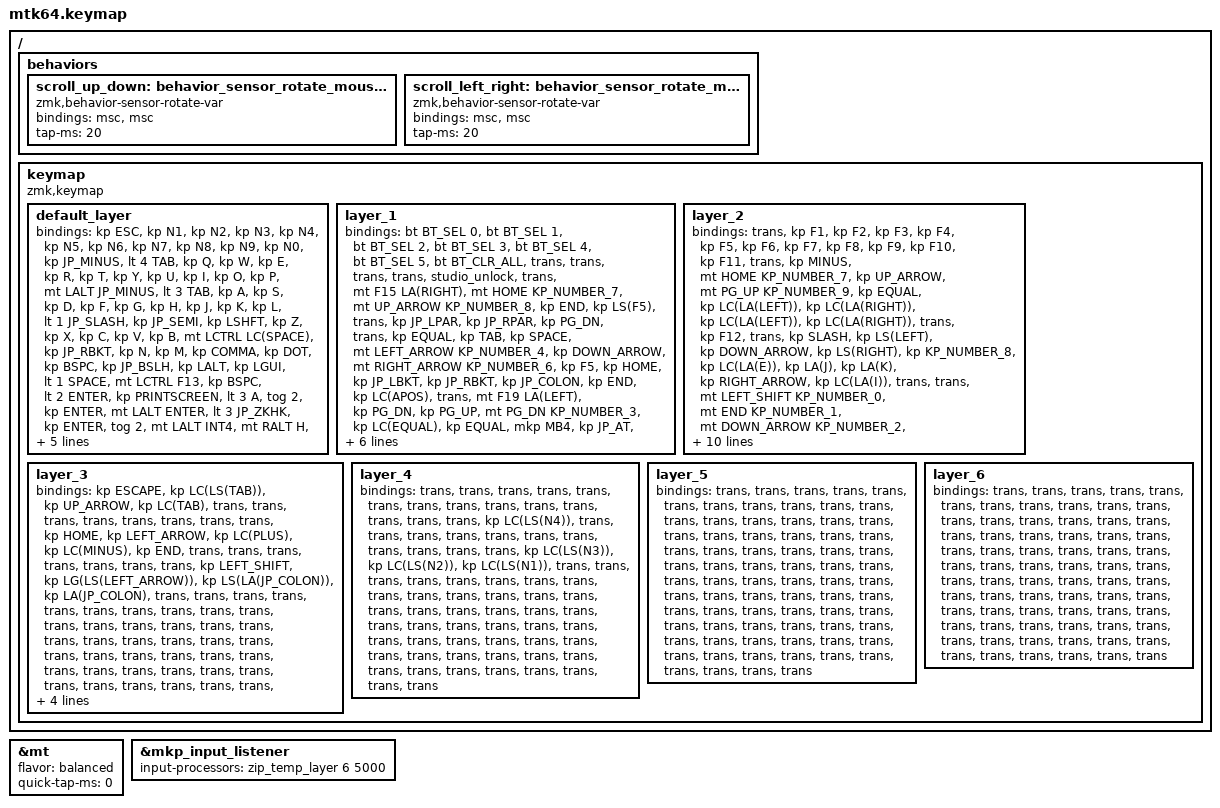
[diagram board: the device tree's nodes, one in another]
#include <input/processors.dtsi>
#include <behaviors.dtsi>
#include <dt-bindings/zmk/bt.h>
#include <dt-bindings/zmk/keys.h>
#include <dt-bindings/zmk/pointing.h>
#include "keycode_japanese.h"

// スクロール量の設定

#define ZMK_POINTING_DEFAULT_SCRL_VAL 100

&mt {
    flavor = "balanced";
    quick-tap-ms = <0>;
};

&mkp_input_listener { input-processors = <&zip_temp_layer 6 5000>; };

/ {
    behaviors {
        // 垂直スクロール用のbehaviorの設定

        scroll_up_down: behavior_sensor_rotate_mouse_wheel_up_down {
            compatible = "zmk,behavior-sensor-rotate-var";
            #sensor-binding-cells = <2>;
            bindings = <&msc>, <&msc>;

            tap-ms = <20>; // スクロールのタップ時間
        };

        // 水平スクロール用のbehaviorの設定

        scroll_left_right: behavior_sensor_rotate_mouse_wheel_left_right {
            compatible = "zmk,behavior-sensor-rotate-var";
            #sensor-binding-cells = <2>;
            bindings = <&msc>, <&msc>;

            tap-ms = <20>; // スクロールのタップ時間
        };
    };
};

/ {
    keymap {
        compatible = "zmk,keymap";

        default_layer {
            bindings = <
&kp ESC  &kp N1  &kp N2  &kp N3  &kp N4  &kp N5  &kp N6  &kp N7  &kp N8  &kp N9  &kp N0  &kp JP_MINUS  &lt 4 TAB  &kp Q  &kp W  &kp E  &kp R  &kp T  &kp Y  &kp U  &kp I  &kp O  &kp P  &mt LALT JP_MINUS  &lt 3 TAB  &kp A  &kp S  &kp D  &kp F  &kp G  &kp H  &kp J  &kp K  &kp L  &lt 1 JP_SLASH  &kp JP_SEMI  &kp LSHFT  &kp Z  &kp X  &kp C  &kp V  &kp B  &mt LCTRL LC(SPACE)  &kp JP_RBKT  &kp N  &kp M  &kp COMMA  &kp DOT  &kp BSPC  &kp JP_BSLH  &kp LALT  &kp LGUI  &lt 1 SPACE  &mt LCTRL F13  &kp BSPC  &lt 2 ENTER  &kp PRINTSCREEN  &lt 3 A  &tog 2  &kp ENTER  &mt LALT ENTER  &lt 3 JP_ZKHK  &kp ENTER  &tog 2  &mt LALT INT4  &mt RALT H  &mo 1  &mo 2  &mo 3  &mo 1  &mo 2  &mo 3  &mo 1  &mo 2  &mo 3
            >;

            sensor-bindings = <
                &inc_dec_kp LEFT_ARROW RIGHT_ARROW
                &inc_dec_kp UP_ARROW   DOWN_ARROW
            >;
        };

        layer_1 {
            bindings = <
&bt BT_SEL 0  &bt BT_SEL 1  &bt BT_SEL 2  &bt BT_SEL 3  &bt BT_SEL 4  &bt BT_SEL 5  &bt BT_CLR_ALL  &trans  &trans  &trans  &trans  &studio_unlock  &trans  &mt F15 LA(RIGHT)  &mt HOME KP_NUMBER_7  &mt UP_ARROW KP_NUMBER_8  &kp END  &kp LS(F5)  &trans  &kp JP_LPAR  &kp JP_RPAR  &kp PG_DN  &trans  &kp EQUAL  &kp TAB  &kp SPACE  &mt LEFT_ARROW KP_NUMBER_4  &kp DOWN_ARROW  &mt RIGHT_ARROW KP_NUMBER_6  &kp F5  &kp HOME  &kp JP_LBKT  &kp JP_RBKT  &kp JP_COLON  &kp END  &kp LC(APOS)  &trans  &mt F19 LA(LEFT)  &kp PG_DN  &kp PG_UP  &mt PG_DN KP_NUMBER_3  &kp LC(EQUAL)  &kp EQUAL  &mkp MB4  &kp JP_AT  &kp JP_AT  &mkp MB2  &mkp MB3  &kp DEL  &trans  &trans  &trans  &mkp MB1  &mkp MB2  &trans  &trans  &kp LC(LS(M))  &kp LC(LA(L))  &trans  &trans  &trans  &trans  &trans  &trans  &mkp MB3  &trans  &trans  &trans  &trans  &trans  &trans  &trans  &trans  &trans  &trans
            >;
        };

        layer_2 {
            bindings = <
&trans  &kp F1  &kp F2  &kp F3  &kp F4  &kp F5  &kp F6  &kp F7  &kp F8  &kp F9  &kp F10  &kp F11  &trans  &kp MINUS  &mt HOME KP_NUMBER_7  &kp UP_ARROW  &mt PG_UP KP_NUMBER_9  &kp EQUAL  &kp LC(LA(LEFT))  &kp LC(LA(RIGHT))  &kp LC(LA(LEFT))  &kp LC(LA(RIGHT))  &trans  &kp F12  &trans  &kp SLASH  &kp LS(LEFT)  &kp DOWN_ARROW  &kp LS(RIGHT)  &kp KP_NUMBER_8  &kp LC(LA(E))  &kp LA(J)  &kp LA(K)  &kp RIGHT_ARROW  &kp LC(LA(I))  &trans  &trans  &mt LEFT_SHIFT KP_NUMBER_0  &mt END KP_NUMBER_1  &mt DOWN_ARROW KP_NUMBER_2  &mt PG_DN KP_NUMBER_3  &kp PERIOD  &kp EQUAL  &mkp MB4  &kp LC(LA(M))  &kp LC(LA(F))  &kp LC(LA(H))  &kp LA(F21)  &kp LA(F22)  &trans  &trans  &trans  &trans  &trans  &trans  &trans  &trans  &trans  &trans  &trans  &trans  &trans  &trans  &trans  &trans  &trans  &trans  &trans  &trans  &trans  &trans  &trans  &trans  &trans  &trans
            >;

            sensor-bindings = <
                &inc_dec_kp TAB LS(TAB) 
                &inc_dec_kp PG_UP PG_DN
            >;
        };

        layer_3 {
            bindings = <
&kp ESCAPE  &kp LC(LS(TAB))  &kp UP_ARROW  &kp LC(TAB)  &trans  &trans  &trans  &trans  &trans  &trans  &trans  &trans  &kp HOME  &kp LEFT_ARROW  &kp LC(PLUS)  &kp LC(MINUS)  &kp END  &trans  &trans  &trans  &trans  &trans  &trans  &trans  &kp LEFT_SHIFT  &kp LG(LS(LEFT_ARROW))  &kp LS(LA(JP_COLON))  &kp LA(JP_COLON)  &trans  &trans  &trans  &trans  &trans  &trans  &trans  &trans  &trans  &trans  &trans  &trans  &trans  &trans  &trans  &trans  &trans  &trans  &trans  &trans  &trans  &trans  &trans  &trans  &trans  &trans  &trans  &trans  &trans  &trans  &trans  &trans  &trans  &trans  &trans  &trans  &trans  &trans  &trans  &trans  &trans  &trans  &trans  &trans  &trans  &trans  &trans
            >;

            sensor-bindings = <
                &inc_dec_kp F17 F18
                &inc_dec_kp PG_UP PG_DN
            >;
        };

        layer_4 {
            bindings = <
&trans  &trans  &trans  &trans  &trans  &trans  &trans  &trans  &trans  &trans  &trans  &trans  &trans  &trans  &kp LC(LS(N4))  &trans  &trans  &trans  &trans  &trans  &trans  &trans  &trans  &trans  &trans  &trans  &kp LC(LS(N3))  &kp LC(LS(N2))  &kp LC(LS(N1))  &trans  &trans  &trans  &trans  &trans  &trans  &trans  &trans  &trans  &trans  &trans  &trans  &trans  &trans  &trans  &trans  &trans  &trans  &trans  &trans  &trans  &trans  &trans  &trans  &trans  &trans  &trans  &trans  &trans  &trans  &trans  &trans  &trans  &trans  &trans  &trans  &trans  &trans  &trans  &trans  &trans  &trans  &trans  &trans  &trans  &trans
            >;
        };

        layer_5 {
            bindings = <
&trans  &trans  &trans  &trans  &trans  &trans  &trans  &trans  &trans  &trans  &trans  &trans  &trans  &trans  &trans  &trans  &trans  &trans  &trans  &trans  &trans  &trans  &trans  &trans  &trans  &trans  &trans  &trans  &trans  &trans  &trans  &trans  &trans  &trans  &trans  &trans  &trans  &trans  &trans  &trans  &trans  &trans  &trans  &trans  &trans  &trans  &trans  &trans  &trans  &trans  &trans  &trans  &trans  &trans  &trans  &trans  &trans  &trans  &trans  &trans  &trans  &trans  &trans  &trans  &trans  &trans  &trans  &trans  &trans  &trans  &trans  &trans  &trans  &trans  &trans
            >;
        };

        layer_6 {
            bindings = <
&trans  &trans  &trans  &trans  &trans  &trans  &trans  &trans  &trans  &trans  &trans  &trans  &trans  &trans  &trans  &trans  &trans  &trans  &trans  &trans  &trans  &trans  &trans  &trans  &trans  &trans  &trans  &trans  &trans  &trans  &trans  &trans  &trans  &trans  &trans  &trans  &trans  &trans  &trans  &trans  &trans  &trans  &trans  &trans  &trans  &trans  &trans  &trans  &trans  &trans  &trans  &trans  &trans  &trans  &trans  &trans  &trans  &trans  &trans  &trans  &trans  &trans  &trans  &trans  &trans  &trans  &trans  &trans  &trans  &trans  &trans
            >;
        };
    };
};
